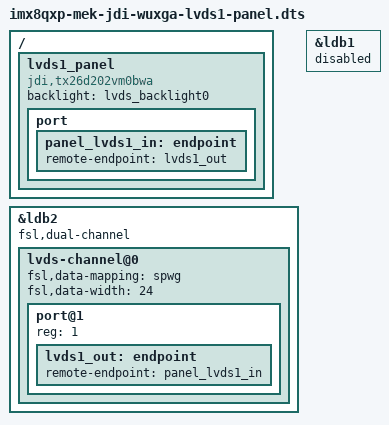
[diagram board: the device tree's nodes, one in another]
// SPDX-License-Identifier: GPL-2.0+

/*
 * Copyright 2019 NXP
 */

#include "imx8qxp-mek-rpmsg.dts"

/ {
	lvds1_panel {
		compatible = "jdi,tx26d202vm0bwa";
		backlight = <&lvds_backlight0>;

		port {
			panel_lvds1_in: endpoint {
				remote-endpoint = <&lvds1_out>;
			};
		};
	};
};

/delete-node/ &it6263_1_in;

&ldb2 {
	fsl,dual-channel;

	lvds-channel@0 {
		fsl,data-mapping = "spwg";
		fsl,data-width = <24>;

		port@1 {
			reg = <1>;

			lvds1_out: endpoint {
				remote-endpoint = <&panel_lvds1_in>;
			};
		};
	};
};

&ldb1 {
	status = "disabled";
};
